# soc register map
Vendor: litex
Registers are 32-bit, read-write, reset 0x0 unless marked. A register's access mark holds for its fields unless they carry their own. Offsets are from the block's base; lines under a group give offsets from that group; [hi:lo] are bit positions; {n}, {i} and the like mark numbered series; 'fields as' and 'values as' point back to an identical list; <NAME> marks a mode.

## Memory map
0x00000000 CTRL size 0xC
0x00000800 PS2 size 0x10

## Further device data
memoryRegions:
  CSR baseAddress=0x00000000 size=0x00010000

## CTRL
Base 0x00000000
0x00 RESET — Write a ``1`` to this register to reset the SoC.
  [0] reset
0x04 SCRATCH reset 0x12345678 — Use this register as a scratch space to verify that software read/write accesses to the Wishbone/CSR bus are working correctly. The initial reset value of 0x1234578 can be used to verify endianness.
0x08 BUS_ERRORS — Total number of Wishbone bus errors (timeouts) since start.

## PS2
Base 0x00000800
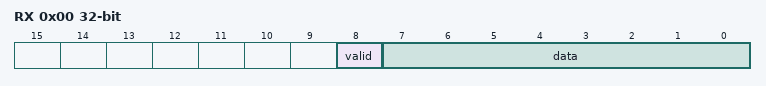
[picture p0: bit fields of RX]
0x00 RX — Receive register
  [8] valid — Data valid
  [7:0] data — Received data
0x04 EV_STATUS — This register contains the current raw level of the data event trigger. Writes to this register have no effect.
  [0] data — Level of the ``data`` event
0x08 EV_PENDING — When a data event occurs, the corresponding bit will be set in this register. To clear the Event, set the corresponding bit in this register.
  [0] data — `1` if a `data` event occurred. This Event is **level triggered** when the signal is **high**.
0x0C EV_ENABLE — This register enables the corresponding data events. Write a ``0`` to this register to disable individual events.
  [0] data — Write a ``1`` to enable the ``data`` Event
